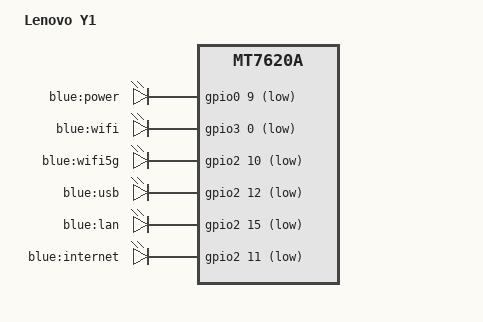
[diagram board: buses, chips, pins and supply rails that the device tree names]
#include "mt7620a_lenovo_newifi-y1.dtsi"

/ {
	compatible = "lenovo,newifi-y1", "ralink,mt7620a-soc";
	model = "Lenovo Y1";

	aliases {
		led-boot = &led_power;
		led-failsafe = &led_power;
		led-running = &led_power;
		led-upgrade = &led_power;
		label-mac-device = &ethernet;
	};

	leds {
		compatible = "gpio-leds";

		led_power: power {
			label = "blue:power";
			gpios = <&gpio0 9 GPIO_ACTIVE_LOW>;
		};

		wlan1 {
			label = "blue:wifi";
			gpios = <&gpio3 0 GPIO_ACTIVE_LOW>;
		};

		wlan2 {
			label = "blue:wifi5g";
			gpios = <&gpio2 10 GPIO_ACTIVE_LOW>;
		};

		usb {
			label = "blue:usb";
			gpios = <&gpio2 12 GPIO_ACTIVE_LOW>;
			trigger-sources = <&ohci_port1>, <&ehci_port1>;
			linux,default-trigger = "usbport";
		};

		lan {
			label = "blue:lan";
			gpios = <&gpio2 15 GPIO_ACTIVE_LOW>;
		};

		internet {
			label = "blue:internet";
			gpios = <&gpio2 11 GPIO_ACTIVE_LOW>;
		};
	};
};

&ethernet {
	pinctrl-names = "default";
	pinctrl-0 = <&ephy_pins>;

	nvmem-cells = <&macaddr_factory_28>;
	nvmem-cell-names = "mac-address";

	mediatek,portmap = "llllw";
};

&factory {
	compatible = "nvmem-cells";
	#address-cells = <1>;
	#size-cells = <1>;

	macaddr_factory_28: macaddr@28 {
		reg = <0x28 0x6>;
	};
};
